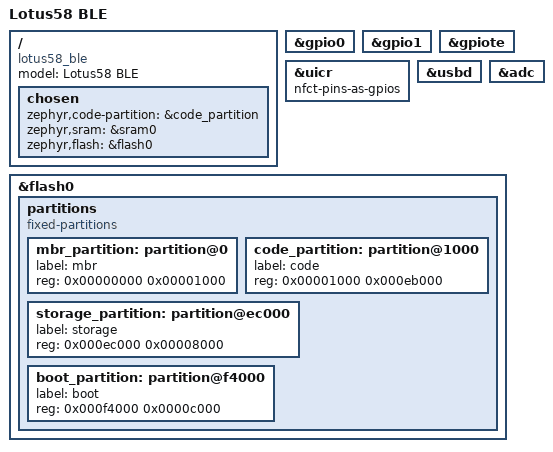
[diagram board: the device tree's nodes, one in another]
// Copyright (c) 2026 Oscar Brandt
// SPDX-License-Identifier: MIT

/dts-v1/;

#include <nordic/nrf52840_qiaa.dtsi>

/ {
	model = "Lotus58 BLE";
	compatible = "lotus58_ble";

	chosen {
		zephyr,code-partition = &code_partition;
		zephyr,sram = &sram0;
		zephyr,flash = &flash0;
	};
};

// Enables GPIO port 0 (pins P0.00 to P0.31) used by the keyboard matrix and underglow data.
&gpio0 {
	status = "okay";
};

// Enables GPIO port 1 (pins P1.00 to P1.15) used by the encoders, underglow power and indicator LED.
&gpio1 {
	status = "okay";
};

// Enables GPIO tasks and events for the keyboard matrix interrupts.
&gpiote {
	status = "okay";
};

// Lifts the reservation of the NFC pins so they can be used as GPIO for the matrix.
&uicr {
	nfct-pins-as-gpios;
};

// Enables USB device driver. Name is needed for ZMK Studio support.
zephyr_udc0: &usbd {
	status = "okay";
};

// Enables the analog to digital converter to measure the battery voltage.
&adc {
	status = "okay";
};

&flash0 {
	partitions {
		compatible = "fixed-partitions";
		#address-cells = <1>;
		#size-cells = <1>;

		mbr_partition: partition@0 {
			label = "mbr";
			reg = <0x00000000 0x00001000>;
		};

		code_partition: partition@1000 {
			label = "code";
			reg = <0x00001000 0x000eb000>;
		};

		storage_partition: partition@ec000 {
			label = "storage";
			reg = <0x000ec000 0x00008000>;
		};

		boot_partition: partition@f4000 {
			label = "boot";
			reg = <0x000f4000 0x0000c000>;
		};
	};
};
